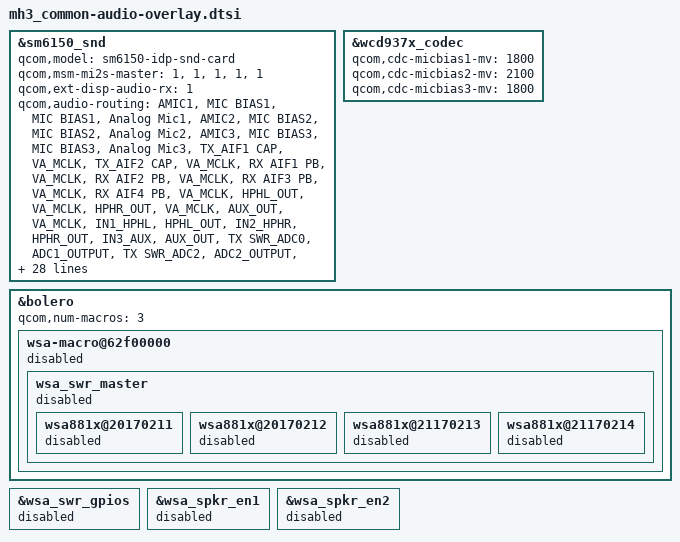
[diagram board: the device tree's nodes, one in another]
/*
 * Copyright (c) 2018, The Linux Foundation. All rights reserved.
 *
 * This program is free software; you can redistribute it and/or modify
 * it under the terms of the GNU General Public License version 2 and
 * only version 2 as published by the Free Software Foundation.
 *
 * This program is distributed in the hope that it will be useful,
 * but WITHOUT ANY WARRANTY; without even the implied warranty of
 * MERCHANTABILITY or FITNESS FOR A PARTICULAR PURPOSE.  See the
 * GNU General Public License for more details.
 */

#include "../../qcom/sm6150-audio-overlay.dtsi"
#include "../mh3_common-sound-es9218.dtsi"
#include "../mh3_common-sound-tas2562.dtsi"

&sm6150_snd {
	qcom,model = "sm6150-idp-snd-card";
	qcom,msm-mi2s-master = <1>, <1>, <1>, <1>, <1>;
	qcom,ext-disp-audio-rx = <1>;
	qcom,audio-routing =
		"AMIC1", "MIC BIAS1",
		"MIC BIAS1", "Analog Mic1",
		"AMIC2", "MIC BIAS2",
		"MIC BIAS2", "Analog Mic2",
		"AMIC3", "MIC BIAS3",
		"MIC BIAS3", "Analog Mic3",
		"TX_AIF1 CAP", "VA_MCLK",
		"TX_AIF2 CAP", "VA_MCLK",
		"RX AIF1 PB", "VA_MCLK",
		"RX AIF2 PB", "VA_MCLK",
		"RX AIF3 PB", "VA_MCLK",
		"RX AIF4 PB", "VA_MCLK",
		"HPHL_OUT", "VA_MCLK",
		"HPHR_OUT", "VA_MCLK",
		"AUX_OUT", "VA_MCLK",
		"IN1_HPHL", "HPHL_OUT",
		"IN2_HPHR", "HPHR_OUT",
		"IN3_AUX", "AUX_OUT",
		"TX SWR_ADC0", "ADC1_OUTPUT",
		"TX SWR_ADC2", "ADC2_OUTPUT",
		"RX_TX DEC0_INP", "TX DEC0 MUX",
		"RX_TX DEC1_INP", "TX DEC1 MUX",
		"RX_TX DEC2_INP", "TX DEC2 MUX",
		"RX_TX DEC3_INP", "TX DEC3 MUX";
	qcom,msm-mbhc-hphl-swh = <1>;
	qcom,msm-mbhc-gnd-swh = <0>;
	qcom,cdc-dmic01-gpios = <&cdc_dmic01_gpios>;
	qcom,cdc-dmic23-gpios = <&cdc_dmic23_gpios>;
	asoc-codec  = <&stub_codec>, <&bolero>, <&ext_disp_audio_codec>;
	asoc-codec-names = "msm-stub-codec.1", "bolero_codec",
			   "msm-ext-disp-audio-codec-rx";
	qcom,wsa-max-devs = <0>;
	qcom,wsa-aux-dev-prefix = "SpkrLeft", "SpkrRight",
				  "SpkrLeft", "SpkrRight";
	qcom,codec-aux-devs = <&wcd937x_codec>;
	qcom,msm_audio_ssr_devs = <&audio_apr>, <&q6core>,
				<&lpi_tlmm>, <&bolero>;

	pinctrl-names = "pri-mi2s-sleep", "pri-mi2s-active", "tert-mi2s-sleep", "tert-mi2s-active";
	pinctrl-0 = <&pri_mi2s_sleep &pri_mi2s_sd0_sleep>;
	pinctrl-1 = <&pri_mi2s_active &pri_mi2s_sd0_active>;
	pinctrl-2 = <&ter_mi2s_sleep &ter_mi2s_sd0_sleep &ter_mi2s_sd1_sleep>;
	pinctrl-3 = <&ter_mi2s_active &ter_mi2s_sd0_active &ter_mi2s_sd1_active>;

	lge,fmradio-lna-enable-gpio = <&tlmm 27 0x00>;
	lna-supply = <&pm6150_l16>;
	lge,fmradio-rf-ctrl-gpio = <&tlmm 87 0x00>;
	spdt-supply = <&pm6150_l16>;
};

&wcd937x_codec {
	qcom,cdc-micbias1-mv = <1800>;
	qcom,cdc-micbias2-mv = <2100>;
	qcom,cdc-micbias3-mv = <1800>;
};

&bolero {
	qcom,num-macros = <3>;
	wsa-macro@62f00000 {
		status = "disabled";
		wsa_swr_master {
			status = "disabled";
			wsa881x@20170211 {
				status = "disabled";
			};
			wsa881x@20170212 {
				status = "disabled";
			};
			wsa881x@21170213 {
				status = "disabled";
			};
			wsa881x@21170214 {
				status = "disabled";
			};
		};
	};
};

&wsa_swr_gpios {
	status = "disabled";
};

&wsa_spkr_en1 {
	status = "disabled";
};

&wsa_spkr_en2 {
	status = "disabled";
};

